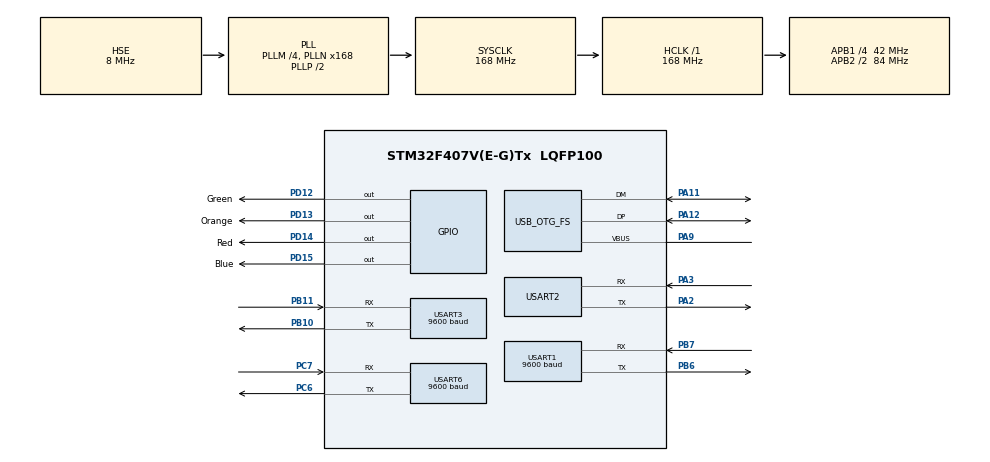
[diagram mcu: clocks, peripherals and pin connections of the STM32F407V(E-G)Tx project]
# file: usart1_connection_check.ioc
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Mcu.Family=STM32F4
Mcu.Name=STM32F407V(E-G)Tx
Mcu.Package=LQFP100
NVIC.PriorityGroup=NVIC_PRIORITYGROUP_0
NVIC.TIM1_BRK_TIM9_IRQn=true\:0\:0\:false\:false\:true\:true\:true\:true
NVIC.USART1_IRQn=true\:0\:0\:false\:false\:true\:true\:true\:true
NVIC.USART2_IRQn=true\:0\:0\:false\:false\:true\:true\:true\:true
NVIC.USART3_IRQn=true\:0\:0\:false\:false\:true\:true\:true\:true
NVIC.USART6_IRQn=true\:0\:0\:false\:false\:true\:true\:true\:true
PA11.Mode=Device_Only
PA11.Signal=USB_OTG_FS_DM
PA12.Mode=Device_Only
PA12.Signal=USB_OTG_FS_DP
PA13.Mode=Serial_Wire
PA13.Signal=SYS_JTMS-SWDIO
PA14.Mode=Serial_Wire
PA14.Signal=SYS_JTCK-SWCLK
PA2.Mode=Asynchronous
PA2.Signal=USART2_TX
PA3.Mode=Asynchronous
PA3.Signal=USART2_RX
PA9.Mode=Activate_VBUS
PA9.Signal=USB_OTG_FS_VBUS
PB10.Mode=Asynchronous
PB10.Signal=USART3_TX
PB11.Mode=Asynchronous
PB11.Signal=USART3_RX
PB6.Mode=Asynchronous
PB6.Signal=USART1_TX
PB7.Mode=Asynchronous
PB7.Signal=USART1_RX
PC6.Mode=Asynchronous
PC6.Signal=USART6_TX
PC7.Mode=Asynchronous
PC7.Signal=USART6_RX
PD12.GPIO_Label=Green
PD12.Signal=GPIO_Output
PD13.GPIO_Label=Orange
PD13.Signal=GPIO_Output
PD14.GPIO_Label=Red
PD14.Signal=GPIO_Output
PD15.GPIO_Label=Blue
PD15.Signal=GPIO_Output
PH0-OSC_IN.Mode=HSE-External-Oscillator
PH0-OSC_IN.Signal=RCC_OSC_IN
PH1-OSC_OUT.Mode=HSE-External-Oscillator
PH1-OSC_OUT.Signal=RCC_OSC_OUT
ProjectManager.HeapSize=0x200
ProjectManager.StackSize=0x400
ProjectManager.TargetToolchain=MDK-ARM V5.32
RCC.48MHZClocksFreq_Value=48000000
RCC.AHBFreq_Value=168000000
RCC.APB1CLKDivider=RCC_HCLK_DIV4
RCC.APB1Freq_Value=42000000
RCC.APB1TimFreq_Value=84000000
RCC.APB2CLKDivider=RCC_HCLK_DIV2
RCC.APB2Freq_Value=84000000
RCC.APB2TimFreq_Value=168000000
RCC.CortexFreq_Value=168000000
RCC.HCLKFreq_Value=168000000
RCC.HSE_VALUE=8000000
RCC.HSI_VALUE=16000000
RCC.LSE_VALUE=32768
RCC.PLLM=4
RCC.PLLN=168
RCC.PLLQ=7
RCC.SYSCLKFreq_VALUE=168000000
RCC.SYSCLKSource=RCC_SYSCLKSOURCE_PLLCLK
RCC.VCOOutputFreq_Value=336000000
TIM9.Period=9999
TIM9.Prescaler=167
USART1.BaudRate=9600
USART1.VirtualMode=VM_ASYNC
USART2.VirtualMode=VM_ASYNC
USART3.BaudRate=9600
USART3.VirtualMode=VM_ASYNC
USART6.BaudRate=9600
USART6.VirtualMode=VM_ASYNC
USB_OTG_FS.VirtualMode=Device_Only
VP_TIM9_VS_ClockSourceINT.Mode=Internal
board=STM32F407G-DISC1

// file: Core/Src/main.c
/* USER CODE BEGIN Header */
/**
  ******************************************************************************
  * @file           : main.c
  * @brief          : Main program body
  ******************************************************************************
  * @attention
  *
  * Copyright (c) 2024 STMicroelectronics.
  * All rights reserved.
  *
  * This software is licensed under terms that can be found in the LICENSE file
  * in the root directory of this software component.
  * If no LICENSE file comes with this software, it is provided AS-IS.
  *
  ******************************************************************************
  */
/* USER CODE END Header */
#include "main.h"
#include "tim.h"
#include "usart.h"
#include "usb_otg.h"
#include "gpio.h"

void SystemClock_Config(void);

/* USER CODE BEGIN 0 */
uint8_t rx_data1[1];
/* USER CODE END 0 */

int main(void)
{

  /* MCU Configuration--------------------------------------------------------*/

  /* Reset of all peripherals, Initializes the Flash interface and the Systick. */
  HAL_Init();

  /* Configure the system clock */
  SystemClock_Config();

  /* Initialize all configured peripherals */
  MX_GPIO_Init();
  MX_USART1_UART_Init();
  MX_USART2_UART_Init();
  MX_USART3_UART_Init();
  MX_USART6_UART_Init();
  MX_USB_OTG_FS_PCD_Init();
  MX_TIM9_Init();
  /* USER CODE BEGIN 2 */
	HAL_UART_Receive(&huart3,rx_data1,1,HAL_MAX_DELAY);
	HAL_TIM_Base_Start_IT(&htim9);
  /* USER CODE END 2 */

  /* Infinite loop */
  while (1)
  {
  }
}

void SystemClock_Config(void)
{
  RCC_OscInitTypeDef RCC_OscInitStruct = {0};
  RCC_ClkInitTypeDef RCC_ClkInitStruct = {0};

  /** Configure the main internal regulator output voltage
  */
  __HAL_RCC_PWR_CLK_ENABLE();
  __HAL_PWR_VOLTAGESCALING_CONFIG(PWR_REGULATOR_VOLTAGE_SCALE1);

  /** Initializes the RCC Oscillators according to the specified parameters
  * in the RCC_OscInitTypeDef structure.
  */
  RCC_OscInitStruct.OscillatorType = RCC_OSCILLATORTYPE_HSE;
  RCC_OscInitStruct.HSEState = RCC_HSE_ON;
  RCC_OscInitStruct.PLL.PLLState = RCC_PLL_ON;
  RCC_OscInitStruct.PLL.PLLSource = RCC_PLLSOURCE_HSE;
  RCC_OscInitStruct.PLL.PLLM = 4;
  RCC_OscInitStruct.PLL.PLLN = 168;
  RCC_OscInitStruct.PLL.PLLP = RCC_PLLP_DIV2;
  RCC_OscInitStruct.PLL.PLLQ = 7;
  if (HAL_RCC_OscConfig(&RCC_OscInitStruct) != HAL_OK)
  {
    Error_Handler();
  }

  /** Initializes the CPU, AHB and APB buses clocks
  */
  RCC_ClkInitStruct.ClockType = RCC_CLOCKTYPE_HCLK|RCC_CLOCKTYPE_SYSCLK
                              |RCC_CLOCKTYPE_PCLK1|RCC_CLOCKTYPE_PCLK2;
  RCC_ClkInitStruct.SYSCLKSource = RCC_SYSCLKSOURCE_PLLCLK;
  RCC_ClkInitStruct.AHBCLKDivider = RCC_SYSCLK_DIV1;
  RCC_ClkInitStruct.APB1CLKDivider = RCC_HCLK_DIV4;
  RCC_ClkInitStruct.APB2CLKDivider = RCC_HCLK_DIV2;

  if (HAL_RCC_ClockConfig(&RCC_ClkInitStruct, FLASH_LATENCY_5) != HAL_OK)
  {
    Error_Handler();
  }
}

void Error_Handler(void)
{
  __disable_irq();
  while (1)
  {
  }
}
